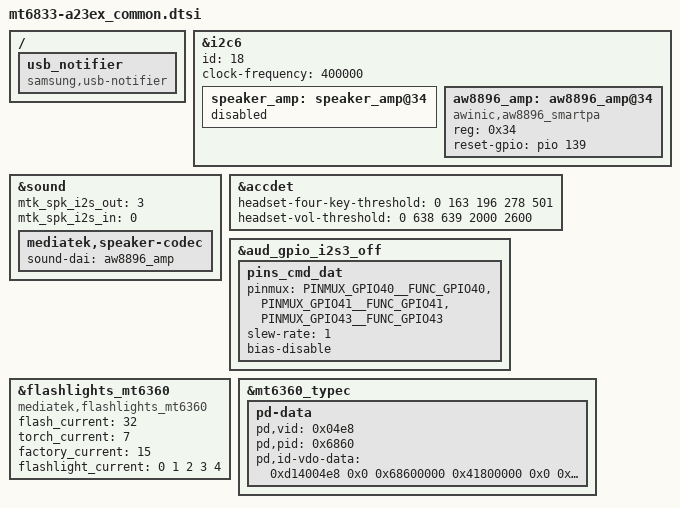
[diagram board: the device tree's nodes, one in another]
/* Generated by Samsung for MTK vendor board
 * If these files should be changed, then please make a sync with MTK
*/

#include "display_lcd_a23ex_common.dtsi"

/* Add Samsung configuration over here */
/ {
	fragment@model {
		target-path = "/";
		__overlay__ {

			usb_notifier {
				compatible = "samsung,usb-notifier";
			};
		};
	};
};

&i2c6 {
	speaker_amp: speaker_amp@34 {
		status = "disabled";
	};
};

&i2c6 {
	status = "okay";
	id = <18>;
	clock-frequency = <400000>;
	#address-cells = <1>;
	#size-cells = <0>;

	aw8896_amp: aw8896_amp@34 {
		compatible = "awinic,aw8896_smartpa";
		#sound-dai-cells = <0>;
		reg = <0x34>;
		reset-gpio = <&pio 139 0>;
		status = "okay";
	};
};

&sound {
	mtk_spk_i2s_out = <3>;
	mtk_spk_i2s_in = <0>;
	mediatek,speaker-codec {
		sound-dai = <&aw8896_amp>;
	};
};

/* accdet start */
&accdet {
	headset-four-key-threshold = <0 163 196 278 501>;
	headset-vol-threshold = <0 638 639 2000 2600>;
};
/* accdet end */

/* I2S gpio configuration */
&aud_gpio_i2s3_off {
	pins_cmd_dat {
		pinmux = <PINMUX_GPIO40__FUNC_GPIO40>,
			 <PINMUX_GPIO41__FUNC_GPIO41>,
			 <PINMUX_GPIO43__FUNC_GPIO43>;
		slew-rate = <1>;
		bias-disable;
	};
};

&flashlights_mt6360 {
	compatible = "mediatek,flashlights_mt6360";
	flash_current = <32>;
	torch_current = <7>;
	factory_current = <15>;
	flashlight_current = <0 1 2 3 4>;
};

&mt6360_typec {
	pd-data {
		pd,vid = <0x04e8>;
		pd,pid = <0x6860>;
		pd,id-vdo-data = <0xd14004e8 0x0 0x68600000
				 0x41800000 0x0 0x21800000>;
	};
};

